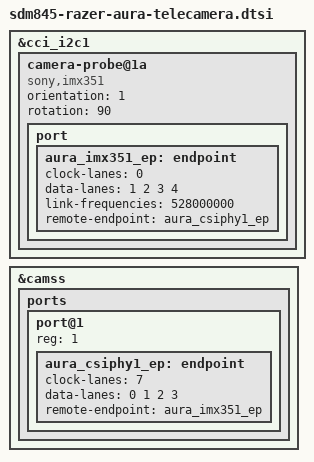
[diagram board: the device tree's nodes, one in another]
// SPDX-License-Identifier: GPL-2.0-only
/* Apply after camera-probe.dtsi: reuse the verified power and CCI1 wiring. */
&cci_i2c1 {
    camera-probe@1a {
        compatible = "sony,imx351";
        orientation = <1>;
        rotation = <90>;
        port {
            aura_imx351_ep: endpoint {
                clock-lanes = <0>;
                data-lanes = <1 2 3 4>;
                link-frequencies = /bits/ 64 <528000000>;
                remote-endpoint = <&aura_csiphy1_ep>;
            };
        };
    };
};
&camss {
    ports {
        port@1 {
            reg = <1>;
            aura_csiphy1_ep: endpoint {
                clock-lanes = <7>;
                data-lanes = <0 1 2 3>;
                remote-endpoint = <&aura_imx351_ep>;
            };
        };
    };
};
